AUTOSAR XML (schema 4-0-3)
package /Svc_NvM
  4 x impl type:
    NvM_BlockIdType: implementation-data-type=uint16
    NvM_RequestResultType: compu {0=NVM_REQ_OK, 1=NVM_REQ_NOT_OK, 2=NVM_REQ_PENDING, 3=NVM_REQ_INTEGRITY_FAILED, 4=NVM_REQ_BLOCK_SKIPPED, 5=NVM_REQ_NV_INVALIDATED, 6=NVM_REQ_CANCELED, 7=NVM_REQ_REDUNDANCY_FAILED, 8=NVM_REQ_RESTORED_FROM_ROM, 9=NVM_MAXVALUE}, implementation-data-type=uint8
    VoidPtr: category=DATA_REFERENCE, sw-pointer-target-props={target-category=VALUE, base-type=void}
    ConstVoidPtr: category=DATA_REFERENCE, sw-pointer-target-props={target-category=VALUE, base-type=void, sw-impl-policy=CONST}
  client server interface NvMNotifyInitBlock: is-service=true, service-kind=NON-VOLATILE-RAM-MANAGER
    operation InitBlock
  client server interface NvMNotifyJobFinished: is-service=true, service-kind=NON-VOLATILE-RAM-MANAGER
    operation JobFinished
      arg ServiceId: type=uint8, direction=IN
      arg JobResult: type=NvM_RequestResultType, direction=IN
  client server interface NvMService: is-service=true, service-kind=NON-VOLATILE-RAM-MANAGER
    7 x operation, all with possible-error=E_NOT_OK:
      GetErrorStatus
        arg RequestResultPtr: type=NvM_RequestResultType, direction=OUT
      ReadBlock
        arg Destination: type=VoidPtr, direction=IN
      WriteBlock
        arg Source: type=ConstVoidPtr, direction=IN
      RestoreBlockDefaults
        arg DstPtr: type=VoidPtr, direction=IN
      CancelJobs
      EraseNvBlock
      InvalidateNvBlock
    error E_NOT_OK: error-code=1
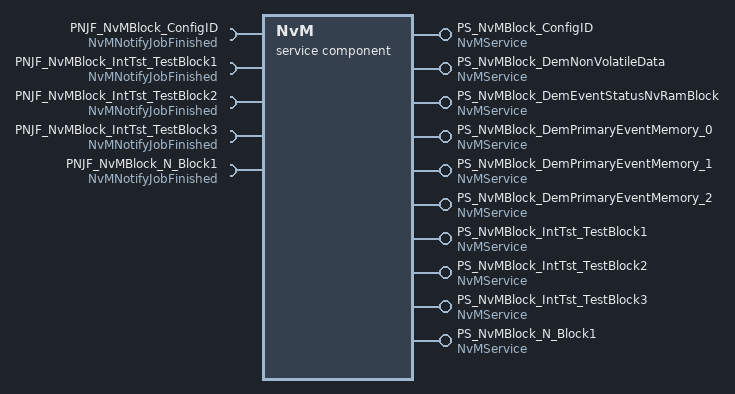
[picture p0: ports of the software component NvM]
  service sw component type NvM
    provide port PS_NvMBlock_ConfigID: provided-interface=NvMService
      provided-com-specs:
        operation=InvalidateNvBlock, queue-length=1
        operation=WriteBlock, queue-length=1
        operation=GetErrorStatus, queue-length=1
        operation=RestoreBlockDefaults, queue-length=1
        operation=ReadBlock, queue-length=1
        operation=CancelJobs, queue-length=1
        operation=EraseNvBlock, queue-length=1
    require port PNJF_NvMBlock_ConfigID: client-com-spec=JobFinished, required-interface=NvMNotifyJobFinished
    6 x provide port, all with provided-interface=NvMService:
      PS_NvMBlock_DemNonVolatileData
        provided-com-specs:
          operation=InvalidateNvBlock, queue-length=1
          operation=WriteBlock, queue-length=1
          operation=GetErrorStatus, queue-length=1
          operation=EraseNvBlock, queue-length=1
          operation=RestoreBlockDefaults, queue-length=1
          operation=CancelJobs, queue-length=1
          operation=ReadBlock, queue-length=1
      PS_NvMBlock_DemEventStatusNvRamBlock
        provided-com-specs:
          operation=RestoreBlockDefaults, queue-length=1
          operation=CancelJobs, queue-length=1
          operation=ReadBlock, queue-length=1
          operation=EraseNvBlock, queue-length=1
          operation=InvalidateNvBlock, queue-length=1
          operation=WriteBlock, queue-length=1
          operation=GetErrorStatus, queue-length=1
      PS_NvMBlock_DemPrimaryEventMemory_0
        provided-com-specs:
          operation=WriteBlock, queue-length=1
          operation=InvalidateNvBlock, queue-length=1
          operation=GetErrorStatus, queue-length=1
          operation=EraseNvBlock, queue-length=1
          operation=CancelJobs, queue-length=1
          operation=ReadBlock, queue-length=1
          operation=RestoreBlockDefaults, queue-length=1
      PS_NvMBlock_DemPrimaryEventMemory_1
        provided-com-specs:
          operation=CancelJobs, queue-length=1
          operation=ReadBlock, queue-length=1
          operation=RestoreBlockDefaults, queue-length=1
          operation=EraseNvBlock, queue-length=1
          operation=WriteBlock, queue-length=1
          operation=InvalidateNvBlock, queue-length=1
          operation=GetErrorStatus, queue-length=1
      PS_NvMBlock_DemPrimaryEventMemory_2
        provided-com-specs:
          operation=GetErrorStatus, queue-length=1
          operation=InvalidateNvBlock, queue-length=1
          operation=WriteBlock, queue-length=1
          operation=EraseNvBlock, queue-length=1
          operation=CancelJobs, queue-length=1
          operation=ReadBlock, queue-length=1
          operation=RestoreBlockDefaults, queue-length=1
      PS_NvMBlock_IntTst_TestBlock1
        provided-com-specs:
          operation=WriteBlock, queue-length=1
          operation=InvalidateNvBlock, queue-length=1
          operation=GetErrorStatus, queue-length=1
          operation=EraseNvBlock, queue-length=1
          operation=ReadBlock, queue-length=1
          operation=CancelJobs, queue-length=1
          operation=RestoreBlockDefaults, queue-length=1
    require port PNJF_NvMBlock_IntTst_TestBlock1: client-com-spec=JobFinished, required-interface=NvMNotifyJobFinished
    provide port PS_NvMBlock_IntTst_TestBlock2: provided-interface=NvMService
      provided-com-specs:
        operation=GetErrorStatus, queue-length=1
        operation=InvalidateNvBlock, queue-length=1
        operation=WriteBlock, queue-length=1
        operation=EraseNvBlock, queue-length=1
        operation=ReadBlock, queue-length=1
        operation=CancelJobs, queue-length=1
        operation=RestoreBlockDefaults, queue-length=1
    require port PNJF_NvMBlock_IntTst_TestBlock2: client-com-spec=JobFinished, required-interface=NvMNotifyJobFinished
    provide port PS_NvMBlock_IntTst_TestBlock3: provided-interface=NvMService
      provided-com-specs:
        operation=EraseNvBlock, queue-length=1
        operation=CancelJobs, queue-length=1
        operation=ReadBlock, queue-length=1
        operation=RestoreBlockDefaults, queue-length=1
        operation=WriteBlock, queue-length=1
        operation=InvalidateNvBlock, queue-length=1
        operation=GetErrorStatus, queue-length=1
    require port PNJF_NvMBlock_IntTst_TestBlock3: client-com-spec=JobFinished, required-interface=NvMNotifyJobFinished
    provide port PS_NvMBlock_N_Block1: provided-interface=NvMService
      provided-com-specs:
        operation=RestoreBlockDefaults, queue-length=1
        operation=CancelJobs, queue-length=1
        operation=ReadBlock, queue-length=1
        operation=EraseNvBlock, queue-length=1
        operation=InvalidateNvBlock, queue-length=1
        operation=WriteBlock, queue-length=1
        operation=GetErrorStatus, queue-length=1
    require port PNJF_NvMBlock_N_Block1: client-com-spec=JobFinished, required-interface=NvMNotifyJobFinished
    behavior IB_NvM: handle-termination-and-restart=NO-SUPPORT
      70 x operation invoked event:
        OperationInvokedEvent_PS_NvMBlock_ConfigID_GetErrorStatus: start-on-event=GetErrorStatus, operation=PS_NvMBlock_ConfigID.GetErrorStatus
        OperationInvokedEvent_PS_NvMBlock_ConfigID_InvalidateNvBlock: start-on-event=InvalidateNvBlock, operation=PS_NvMBlock_ConfigID.InvalidateNvBlock
        OperationInvokedEvent_PS_NvMBlock_ConfigID_WriteBlock: start-on-event=WriteBlock, operation=PS_NvMBlock_ConfigID.WriteBlock
        OperationInvokedEvent_PS_NvMBlock_ConfigID_ReadBlock: start-on-event=ReadBlock, operation=PS_NvMBlock_ConfigID.ReadBlock
        OperationInvokedEvent_PS_NvMBlock_ConfigID_CancelJobs: start-on-event=CancelJobs, operation=PS_NvMBlock_ConfigID.CancelJobs
        OperationInvokedEvent_PS_NvMBlock_ConfigID_RestoreBlockDefaults: start-on-event=RestoreBlockDefaults, operation=PS_NvMBlock_ConfigID.RestoreBlockDefaults
        OperationInvokedEvent_PS_NvMBlock_ConfigID_EraseNvBlock: start-on-event=EraseNvBlock, operation=PS_NvMBlock_ConfigID.EraseNvBlock
        OperationInvokedEvent_PS_NvMBlock_DemNonVolatileData_WriteBlock: start-on-event=WriteBlock, operation=PS_NvMBlock_DemNonVolatileData.WriteBlock
        OperationInvokedEvent_PS_NvMBlock_DemNonVolatileData_InvalidateNvBlock: start-on-event=InvalidateNvBlock, operation=PS_NvMBlock_DemNonVolatileData.InvalidateNvBlock
        OperationInvokedEvent_PS_NvMBlock_DemNonVolatileData_GetErrorStatus: start-on-event=GetErrorStatus, operation=PS_NvMBlock_DemNonVolatileData.GetErrorStatus
        OperationInvokedEvent_PS_NvMBlock_DemNonVolatileData_CancelJobs: start-on-event=CancelJobs, operation=PS_NvMBlock_DemNonVolatileData.CancelJobs
        OperationInvokedEvent_PS_NvMBlock_DemNonVolatileData_ReadBlock: start-on-event=ReadBlock, operation=PS_NvMBlock_DemNonVolatileData.ReadBlock
        OperationInvokedEvent_PS_NvMBlock_DemNonVolatileData_RestoreBlockDefaults: start-on-event=RestoreBlockDefaults, operation=PS_NvMBlock_DemNonVolatileData.RestoreBlockDefaults
        OperationInvokedEvent_PS_NvMBlock_DemNonVolatileData_EraseNvBlock: start-on-event=EraseNvBlock, operation=PS_NvMBlock_DemNonVolatileData.EraseNvBlock
        OperationInvokedEvent_PS_NvMBlock_DemEventStatusNvRamBlock_InvalidateNvBlock: start-on-event=InvalidateNvBlock, operation=PS_NvMBlock_DemEventStatusNvRamBlock.InvalidateNvBlock
        OperationInvokedEvent_PS_NvMBlock_DemEventStatusNvRamBlock_GetErrorStatus: start-on-event=GetErrorStatus, operation=PS_NvMBlock_DemEventStatusNvRamBlock.GetErrorStatus
        OperationInvokedEvent_PS_NvMBlock_DemEventStatusNvRamBlock_WriteBlock: start-on-event=WriteBlock, operation=PS_NvMBlock_DemEventStatusNvRamBlock.WriteBlock
        OperationInvokedEvent_PS_NvMBlock_DemEventStatusNvRamBlock_RestoreBlockDefaults: start-on-event=RestoreBlockDefaults, operation=PS_NvMBlock_DemEventStatusNvRamBlock.RestoreBlockDefaults
        OperationInvokedEvent_PS_NvMBlock_DemEventStatusNvRamBlock_CancelJobs: start-on-event=CancelJobs, operation=PS_NvMBlock_DemEventStatusNvRamBlock.CancelJobs
        OperationInvokedEvent_PS_NvMBlock_DemEventStatusNvRamBlock_ReadBlock: start-on-event=ReadBlock, operation=PS_NvMBlock_DemEventStatusNvRamBlock.ReadBlock
        OperationInvokedEvent_PS_NvMBlock_DemEventStatusNvRamBlock_EraseNvBlock: start-on-event=EraseNvBlock, operation=PS_NvMBlock_DemEventStatusNvRamBlock.EraseNvBlock
        OperationInvokedEvent_PS_NvMBlock_DemPrimaryEventMemory_0_GetErrorStatus: start-on-event=GetErrorStatus, operation=PS_NvMBlock_DemPrimaryEventMemory_0.GetErrorStatus
        OperationInvokedEvent_PS_NvMBlock_DemPrimaryEventMemory_0_InvalidateNvBlock: start-on-event=InvalidateNvBlock, operation=PS_NvMBlock_DemPrimaryEventMemory_0.InvalidateNvBlock
        OperationInvokedEvent_PS_NvMBlock_DemPrimaryEventMemory_0_WriteBlock: start-on-event=WriteBlock, operation=PS_NvMBlock_DemPrimaryEventMemory_0.WriteBlock
        OperationInvokedEvent_PS_NvMBlock_DemPrimaryEventMemory_0_EraseNvBlock: start-on-event=EraseNvBlock, operation=PS_NvMBlock_DemPrimaryEventMemory_0.EraseNvBlock
        OperationInvokedEvent_PS_NvMBlock_DemPrimaryEventMemory_0_CancelJobs: start-on-event=CancelJobs, operation=PS_NvMBlock_DemPrimaryEventMemory_0.CancelJobs
        OperationInvokedEvent_PS_NvMBlock_DemPrimaryEventMemory_0_ReadBlock: start-on-event=ReadBlock, operation=PS_NvMBlock_DemPrimaryEventMemory_0.ReadBlock
        OperationInvokedEvent_PS_NvMBlock_DemPrimaryEventMemory_0_RestoreBlockDefaults: start-on-event=RestoreBlockDefaults, operation=PS_NvMBlock_DemPrimaryEventMemory_0.RestoreBlockDefaults
        OperationInvokedEvent_PS_NvMBlock_DemPrimaryEventMemory_1_WriteBlock: start-on-event=WriteBlock, operation=PS_NvMBlock_DemPrimaryEventMemory_1.WriteBlock
        OperationInvokedEvent_PS_NvMBlock_DemPrimaryEventMemory_1_InvalidateNvBlock: start-on-event=InvalidateNvBlock, operation=PS_NvMBlock_DemPrimaryEventMemory_1.InvalidateNvBlock
        OperationInvokedEvent_PS_NvMBlock_DemPrimaryEventMemory_1_GetErrorStatus: start-on-event=GetErrorStatus, operation=PS_NvMBlock_DemPrimaryEventMemory_1.GetErrorStatus
        OperationInvokedEvent_PS_NvMBlock_DemPrimaryEventMemory_1_EraseNvBlock: start-on-event=EraseNvBlock, operation=PS_NvMBlock_DemPrimaryEventMemory_1.EraseNvBlock
        OperationInvokedEvent_PS_NvMBlock_DemPrimaryEventMemory_1_CancelJobs: start-on-event=CancelJobs, operation=PS_NvMBlock_DemPrimaryEventMemory_1.CancelJobs
        OperationInvokedEvent_PS_NvMBlock_DemPrimaryEventMemory_1_ReadBlock: start-on-event=ReadBlock, operation=PS_NvMBlock_DemPrimaryEventMemory_1.ReadBlock
        OperationInvokedEvent_PS_NvMBlock_DemPrimaryEventMemory_1_RestoreBlockDefaults: start-on-event=RestoreBlockDefaults, operation=PS_NvMBlock_DemPrimaryEventMemory_1.RestoreBlockDefaults
        OperationInvokedEvent_PS_NvMBlock_DemPrimaryEventMemory_2_GetErrorStatus: start-on-event=GetErrorStatus, operation=PS_NvMBlock_DemPrimaryEventMemory_2.GetErrorStatus
        OperationInvokedEvent_PS_NvMBlock_DemPrimaryEventMemory_2_InvalidateNvBlock: start-on-event=InvalidateNvBlock, operation=PS_NvMBlock_DemPrimaryEventMemory_2.InvalidateNvBlock
        OperationInvokedEvent_PS_NvMBlock_DemPrimaryEventMemory_2_WriteBlock: start-on-event=WriteBlock, operation=PS_NvMBlock_DemPrimaryEventMemory_2.WriteBlock
        OperationInvokedEvent_PS_NvMBlock_DemPrimaryEventMemory_2_ReadBlock: start-on-event=ReadBlock, operation=PS_NvMBlock_DemPrimaryEventMemory_2.ReadBlock
        OperationInvokedEvent_PS_NvMBlock_DemPrimaryEventMemory_2_CancelJobs: start-on-event=CancelJobs, operation=PS_NvMBlock_DemPrimaryEventMemory_2.CancelJobs
        OperationInvokedEvent_PS_NvMBlock_DemPrimaryEventMemory_2_RestoreBlockDefaults: start-on-event=RestoreBlockDefaults, operation=PS_NvMBlock_DemPrimaryEventMemory_2.RestoreBlockDefaults
        OperationInvokedEvent_PS_NvMBlock_DemPrimaryEventMemory_2_EraseNvBlock: start-on-event=EraseNvBlock, operation=PS_NvMBlock_DemPrimaryEventMemory_2.EraseNvBlock
        OperationInvokedEvent_PS_NvMBlock_IntTst_TestBlock1_EraseNvBlock: start-on-event=EraseNvBlock, operation=PS_NvMBlock_IntTst_TestBlock1.EraseNvBlock
        OperationInvokedEvent_PS_NvMBlock_IntTst_TestBlock1_CancelJobs: start-on-event=CancelJobs, operation=PS_NvMBlock_IntTst_TestBlock1.CancelJobs
        OperationInvokedEvent_PS_NvMBlock_IntTst_TestBlock1_ReadBlock: start-on-event=ReadBlock, operation=PS_NvMBlock_IntTst_TestBlock1.ReadBlock
        OperationInvokedEvent_PS_NvMBlock_IntTst_TestBlock1_RestoreBlockDefaults: start-on-event=RestoreBlockDefaults, operation=PS_NvMBlock_IntTst_TestBlock1.RestoreBlockDefaults
        OperationInvokedEvent_PS_NvMBlock_IntTst_TestBlock1_WriteBlock: start-on-event=WriteBlock, operation=PS_NvMBlock_IntTst_TestBlock1.WriteBlock
        OperationInvokedEvent_PS_NvMBlock_IntTst_TestBlock1_InvalidateNvBlock: start-on-event=InvalidateNvBlock, operation=PS_NvMBlock_IntTst_TestBlock1.InvalidateNvBlock
        OperationInvokedEvent_PS_NvMBlock_IntTst_TestBlock1_GetErrorStatus: start-on-event=GetErrorStatus, operation=PS_NvMBlock_IntTst_TestBlock1.GetErrorStatus
        OperationInvokedEvent_PS_NvMBlock_IntTst_TestBlock2_WriteBlock: start-on-event=WriteBlock, operation=PS_NvMBlock_IntTst_TestBlock2.WriteBlock
        OperationInvokedEvent_PS_NvMBlock_IntTst_TestBlock2_InvalidateNvBlock: start-on-event=InvalidateNvBlock, operation=PS_NvMBlock_IntTst_TestBlock2.InvalidateNvBlock
        OperationInvokedEvent_PS_NvMBlock_IntTst_TestBlock2_GetErrorStatus: start-on-event=GetErrorStatus, operation=PS_NvMBlock_IntTst_TestBlock2.GetErrorStatus
        OperationInvokedEvent_PS_NvMBlock_IntTst_TestBlock2_EraseNvBlock: start-on-event=EraseNvBlock, operation=PS_NvMBlock_IntTst_TestBlock2.EraseNvBlock
        OperationInvokedEvent_PS_NvMBlock_IntTst_TestBlock2_ReadBlock: start-on-event=ReadBlock, operation=PS_NvMBlock_IntTst_TestBlock2.ReadBlock
        OperationInvokedEvent_PS_NvMBlock_IntTst_TestBlock2_CancelJobs: start-on-event=CancelJobs, operation=PS_NvMBlock_IntTst_TestBlock2.CancelJobs
        OperationInvokedEvent_PS_NvMBlock_IntTst_TestBlock2_RestoreBlockDefaults: start-on-event=RestoreBlockDefaults, operation=PS_NvMBlock_IntTst_TestBlock2.RestoreBlockDefaults
        OperationInvokedEvent_PS_NvMBlock_IntTst_TestBlock3_InvalidateNvBlock: start-on-event=InvalidateNvBlock, operation=PS_NvMBlock_IntTst_TestBlock3.InvalidateNvBlock
        OperationInvokedEvent_PS_NvMBlock_IntTst_TestBlock3_WriteBlock: start-on-event=WriteBlock, operation=PS_NvMBlock_IntTst_TestBlock3.WriteBlock
        OperationInvokedEvent_PS_NvMBlock_IntTst_TestBlock3_GetErrorStatus: start-on-event=GetErrorStatus, operation=PS_NvMBlock_IntTst_TestBlock3.GetErrorStatus
        OperationInvokedEvent_PS_NvMBlock_IntTst_TestBlock3_RestoreBlockDefaults: start-on-event=RestoreBlockDefaults, operation=PS_NvMBlock_IntTst_TestBlock3.RestoreBlockDefaults
        OperationInvokedEvent_PS_NvMBlock_IntTst_TestBlock3_ReadBlock: start-on-event=ReadBlock, operation=PS_NvMBlock_IntTst_TestBlock3.ReadBlock
        OperationInvokedEvent_PS_NvMBlock_IntTst_TestBlock3_CancelJobs: start-on-event=CancelJobs, operation=PS_NvMBlock_IntTst_TestBlock3.CancelJobs
        OperationInvokedEvent_PS_NvMBlock_IntTst_TestBlock3_EraseNvBlock: start-on-event=EraseNvBlock, operation=PS_NvMBlock_IntTst_TestBlock3.EraseNvBlock
        OperationInvokedEvent_PS_NvMBlock_N_Block1_RestoreBlockDefaults: start-on-event=RestoreBlockDefaults, operation=PS_NvMBlock_N_Block1.RestoreBlockDefaults
        OperationInvokedEvent_PS_NvMBlock_N_Block1_CancelJobs: start-on-event=CancelJobs, operation=PS_NvMBlock_N_Block1.CancelJobs
        OperationInvokedEvent_PS_NvMBlock_N_Block1_ReadBlock: start-on-event=ReadBlock, operation=PS_NvMBlock_N_Block1.ReadBlock
        OperationInvokedEvent_PS_NvMBlock_N_Block1_EraseNvBlock: start-on-event=EraseNvBlock, operation=PS_NvMBlock_N_Block1.EraseNvBlock
        OperationInvokedEvent_PS_NvMBlock_N_Block1_InvalidateNvBlock: start-on-event=InvalidateNvBlock, operation=PS_NvMBlock_N_Block1.InvalidateNvBlock
        OperationInvokedEvent_PS_NvMBlock_N_Block1_WriteBlock: start-on-event=WriteBlock, operation=PS_NvMBlock_N_Block1.WriteBlock
        OperationInvokedEvent_PS_NvMBlock_N_Block1_GetErrorStatus: start-on-event=GetErrorStatus, operation=PS_NvMBlock_N_Block1.GetErrorStatus
      port-api-options:
        {enable-take-address=false, indirect-api=false, port-defined-argument-value{value=Block1:1, value-type=NvM_BlockIdType}, port=PS_NvMBlock_ConfigID}
        {enable-take-address=false, indirect-api=false, port-defined-argument-value{value=Block2:2, value-type=NvM_BlockIdType}, port=PS_NvMBlock_DemNonVolatileData}
        {enable-take-address=false, indirect-api=false, port-defined-argument-value{value=Block3:3, value-type=NvM_BlockIdType}, port=PS_NvMBlock_DemEventStatusNvRamBlock}
        {enable-take-address=false, indirect-api=false, port-defined-argument-value{value=Block4:4, value-type=NvM_BlockIdType}, port=PS_NvMBlock_DemPrimaryEventMemory_0}
        {enable-take-address=false, indirect-api=false, port-defined-argument-value{value=Block5:5, value-type=NvM_BlockIdType}, port=PS_NvMBlock_DemPrimaryEventMemory_1}
        {enable-take-address=false, indirect-api=false, port-defined-argument-value{value=Block6:6, value-type=NvM_BlockIdType}, port=PS_NvMBlock_DemPrimaryEventMemory_2}
        {enable-take-address=false, indirect-api=false, port-defined-argument-value{value=Block7:7, value-type=NvM_BlockIdType}, port=PS_NvMBlock_IntTst_TestBlock1}
        {enable-take-address=false, indirect-api=false, port-defined-argument-value{value=Block8:8, value-type=NvM_BlockIdType}, port=PS_NvMBlock_IntTst_TestBlock2}
        {enable-take-address=false, indirect-api=false, port-defined-argument-value{value=Block9:9, value-type=NvM_BlockIdType}, port=PS_NvMBlock_IntTst_TestBlock3}
        {enable-take-address=false, indirect-api=false, port-defined-argument-value{value=Block10:10, value-type=NvM_BlockIdType}, port=PS_NvMBlock_N_Block1}
      8 x runnable:
        RestoreBlockDefaults: arguments=[symbol=BlockId, symbol=NvM_DstPtr], can-be-invoked-concurrently=true, symbol=NvM_RestoreBlockDefaults
        ReadBlock: arguments=[symbol=BlockId, symbol=NvM_DstPtr], can-be-invoked-concurrently=true, symbol=NvM_ReadBlock
        CancelJobs: runnable-entity-argument=symbol=BlockId, can-be-invoked-concurrently=true, symbol=NvM_CancelJobs
        EraseNvBlock: runnable-entity-argument=symbol=BlockId, can-be-invoked-concurrently=true, symbol=NvM_EraseNvBlock
        InvalidateNvBlock: runnable-entity-argument=symbol=BlockId, can-be-invoked-concurrently=true, symbol=NvM_InvalidateNvBlock
        WriteBlock: arguments=[symbol=BlockId, symbol=NvM_SrcPtr], can-be-invoked-concurrently=true, symbol=NvM_WriteBlock
        GetErrorStatus: arguments=[symbol=BlockId, symbol=RequestResultPtr], can-be-invoked-concurrently=true, symbol=NvM_GetErrorStatus
        MainFunction: symbol=NvM_MainFunction
          5 x sync call, all with timeout=0.0:
            SynchronousServerCallPoint_JF_NvMBlock_ConfigID: operation=PNJF_NvMBlock_ConfigID.JobFinished
            SynchronousServerCallPoint_JF_NvMBlock_IntTst_TestBlock{1..3}: operation=PNJF_NvMBlock_IntTst_TestBlock{1..3}.JobFinished
            SynchronousServerCallPoint_JF_NvMBlock_N_Block1: operation=PNJF_NvMBlock_N_Block1.JobFinished
  swc implementation SwcImplementation_NvM: programming-language=C, sw-version=1.3.5, swc-bsw-mapping=SwcBswMapping_NvM, vendor-id=59, behavior=IB_NvM
    code-descriptors:
      code Code: artifact-descriptors=autosar-engineering-object={short-label=NvM, category=SWOBJ}
    resource consumption ResourceConsumption
  swc bsw mapping SwcBswMapping_NvM: bsw-behavior=BswInternalBehavior_NvM, swc-bsw-runnable-mapping{bsw-entity=BSE_NvM, swc-runnable=MainFunction}, swc-behavior=IB_NvM
